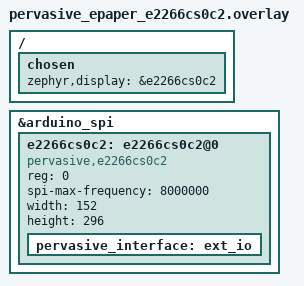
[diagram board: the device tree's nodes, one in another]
/*
 * The confidential and proprietary information contained in this file may
 * only be used by a person authorised under and to the extent permitted
 * by a subsisting licensing agreement from Atmosic.
 *
 * Copyright (c) Atmosic 2024-2025
 *
 * This entire notice must be reproduced on all copies of this file
 * and copies of this file may only be made by a person if such person is
 * permitted to do so under the terms of a subsisting license agreement
 * from Atmosic.
 */

/ {
	chosen {
		zephyr,display = &e2266cs0c2;
	};
};

&arduino_spi {
	status = "okay";

	e2266cs0c2: e2266cs0c2@0 {
		compatible = "pervasive,e2266cs0c2";
		reg = <0>;
		spi-max-frequency = <8000000>;
		width = <152>;
		height = <296>;

		pervasive_interface: ext_io {
			// Please defined them board overlay file.
			// dc-gpios = <&gpio0 x GPIO_ACTIVE_LOW>;
			// reset-gpios = <&gpio0 x GPIO_ACTIVE_LOW>;
			// busy-gpios = <&gpio0 x GPIO_ACTIVE_HIGH>;
			// pc-gpios = ... if existing.
		};
	};
};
